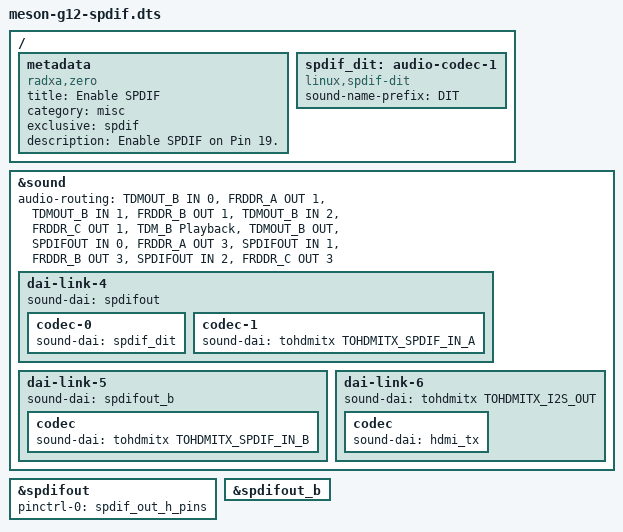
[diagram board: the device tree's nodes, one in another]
/dts-v1/;
/plugin/;

#include <dt-bindings/sound/meson-g12a-tohdmitx.h>

/ {
	metadata {
		title = "Enable SPDIF";
 		compatible = "radxa,zero", "radxa,zero2";
 		category = "misc";
 		exclusive = "spdif";
		description = "Enable SPDIF on Pin 19.";
	};

	fragment@0 {
		target-path = "/";

		__overlay__ {
			spdif_dit: audio-codec-1 {
				#sound-dai-cells = <0>;
				compatible = "linux,spdif-dit";
				status = "okay";
				sound-name-prefix = "DIT";
			};
		};
	};

	fragment@1 {
		target = <&sound>;

		__overlay__ {
			audio-routing = "TDMOUT_B IN 0", "FRDDR_A OUT 1",
							"TDMOUT_B IN 1", "FRDDR_B OUT 1",
							"TDMOUT_B IN 2", "FRDDR_C OUT 1",
							"TDM_B Playback", "TDMOUT_B OUT",
							"SPDIFOUT IN 0", "FRDDR_A OUT 3",
							"SPDIFOUT IN 1", "FRDDR_B OUT 3",
							"SPDIFOUT IN 2", "FRDDR_C OUT 3";
			dai-link-4 {
				sound-dai = <&spdifout>;

				codec-0 {
					sound-dai = <&spdif_dit>;
				};

				codec-1 {
					sound-dai = <&tohdmitx TOHDMITX_SPDIF_IN_A>;
 				};
			};

			dai-link-5 {
 				sound-dai = <&spdifout_b>;

				codec {
 					sound-dai = <&tohdmitx TOHDMITX_SPDIF_IN_B>;
				};
			};

			dai-link-6 {
				sound-dai = <&tohdmitx TOHDMITX_I2S_OUT>;

				codec {
					sound-dai = <&hdmi_tx>;
				};
			};
		};
	};

	fragment@2 {
		target = <&spdifout>;

		__overlay__ {
			pinctrl-0 = <&spdif_out_h_pins>;
			pinctrl-names = "default";
			status = "okay";
		};
	};

	fragment@3 {
		target = <&spdifout_b>;

		 __overlay__ {
			 status = "okay";
		};
	};
};
